VERSION "Demo Aboy Canbus"

NS_ :

BS_:

BU_: ECM ABS BCM

BO_ 809 ENGINE_TEMP: 8 ECM
 SG_ COOLANT_TEMP : 8|8@1+ (0.75,-48) [-48|143] "degC" Vector__XXX

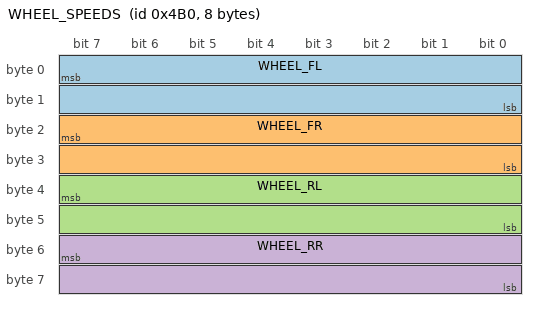
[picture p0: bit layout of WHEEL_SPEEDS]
BO_ 1200 WHEEL_SPEEDS: 8 ABS
 SG_ WHEEL_FL : 7|16@0+ (0.01,0) [0|655] "km/h" Vector__XXX
 SG_ WHEEL_FR : 23|16@0+ (0.01,0) [0|655] "km/h" Vector__XXX
 SG_ WHEEL_RL : 39|16@0+ (0.01,0) [0|655] "km/h" Vector__XXX
 SG_ WHEEL_RR : 55|16@0+ (0.01,0) [0|655] "km/h" Vector__XXX

BO_ 688 STEERING: 5 ABS
 SG_ STEER_ANGLE : 0|16@1- (0.1,0) [-780|780] "deg" Vector__XXX
 SG_ COUNTER : 36|4@1+ (1,0) [0|15] "" Vector__XXX

CM_ BO_ 809 "Engine temperature (demo)";
CM_ BO_ 1200 "Wheel speeds (demo)";
CM_ BO_ 688 "Steering angle (demo)";
